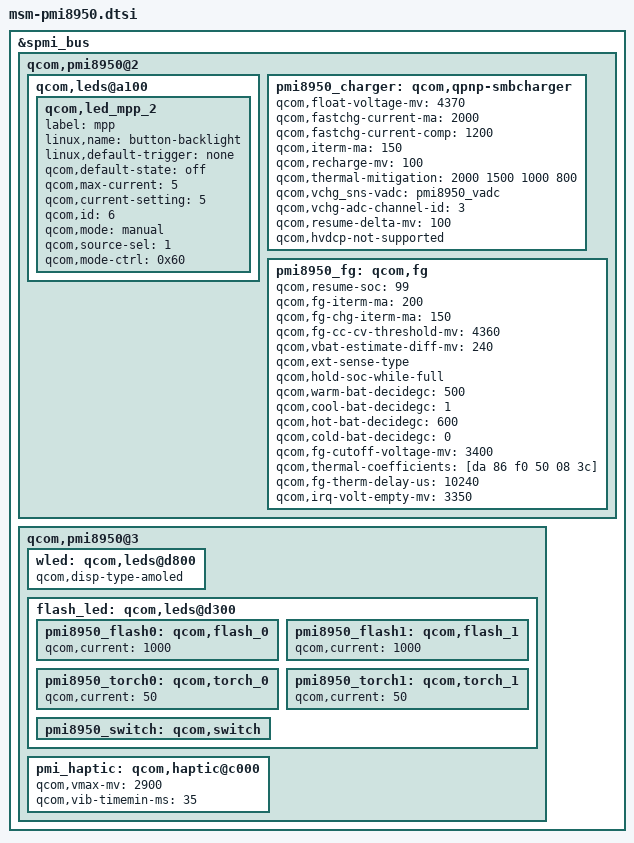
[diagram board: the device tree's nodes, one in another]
/* Copyright (c) 2015-2017, The Linux Foundation. All rights reserved.
 *
 * This program is free software; you can redistribute it and/or modify
 * it under the terms of the GNU General Public License version 2 and
 * only version 2 as published by the Free Software Foundation.
 *
 * This program is distributed in the hope that it will be useful,
 * but WITHOUT ANY WARRANTY; without even the implied warranty of
 * MERCHANTABILITY or FITNESS FOR A PARTICULAR PURPOSE.  See the
 * GNU General Public License for more details.
 */

#include "../msm-pmi8950.dtsi"

&spmi_bus {
	qcom,pmi8950@2 {
		qcom,leds@a100 {
			status = "okay";
			qcom,led_mpp_2 {
				label = "mpp";
				linux,name = "button-backlight";
				linux,default-trigger = "none";
				qcom,default-state = "off";
				qcom,max-current = <5>;
				qcom,current-setting = <5>;
				qcom,id = <6>;
				qcom,mode = "manual";
				qcom,source-sel = <1>;
				qcom,mode-ctrl = <0x60>;
			};
		};

		pmi8950_charger: qcom,qpnp-smbcharger {
			/delete-property/ qcom,parallel-usb-min-current-ma;
			/delete-property/ qcom,parallel-usb-9v-min-current-ma;
			/delete-property/ qcom,parallel-allowed-lowering-ma;

			qcom,float-voltage-mv = <4370>;
			qcom,fastchg-current-ma = <2000>;
			qcom,fastchg-current-comp = <1200>;
			qcom,iterm-ma = <150>;
			qcom,recharge-mv = <100>;
			qcom,thermal-mitigation = <2000 1500 1000 800>;
			qcom,vchg_sns-vadc = <&pmi8950_vadc>;
			qcom,vchg-adc-channel-id = <3>;
			qcom,resume-delta-mv = <100>;
			qcom,hvdcp-not-supported;
		};

		pmi8950_fg: qcom,fg {
			qcom,resume-soc = <99>;
			qcom,fg-iterm-ma = <200>;
			qcom,fg-chg-iterm-ma = <150>;
			qcom,fg-cc-cv-threshold-mv = <4360>;
			qcom,vbat-estimate-diff-mv = <240>;
			qcom,ext-sense-type;
			qcom,hold-soc-while-full;
			qcom,warm-bat-decidegc = <500>;
			qcom,cool-bat-decidegc = <1>;
			qcom,hot-bat-decidegc = <600>;
			qcom,cold-bat-decidegc = <0>;
			qcom,fg-cutoff-voltage-mv = <3400>;
			qcom,thermal-coefficients = [da 86 f0 50 08 3c];
			qcom,fg-therm-delay-us = <10240>;
			qcom,irq-volt-empty-mv = <3350>;
		};
	};

	qcom,pmi8950@3 {
		wled: qcom,leds@d800 {
			qcom,disp-type-amoled;
		};

		flash_led: qcom,leds@d300 {
			pmi8950_flash0: qcom,flash_0 {
				qcom,current = <1000>;
			};

			pmi8950_flash1: qcom,flash_1 {
				qcom,current = <1000>;
			};

			pmi8950_torch0: qcom,torch_0 {
				qcom,current = <50>;
			};

			pmi8950_torch1: qcom,torch_1 {
				qcom,current = <50>;
			};

			pmi8950_switch: qcom,switch {
				/delete-node/ reg0;
			};
		};

		pmi_haptic: qcom,haptic@c000 {
			/delete-property/ vcc_pon-supply;
			/delete-property/ qcom,en-brake;
			/delete-property/ qcom,use-sc-irq;

			status = "okay";
			qcom,vmax-mv = <2900>;
			qcom,vib-timemin-ms = <35>;
		};
	};
};

